# CIC register map
Vendor: Texas Instruments
Peripheral module from a debugger description file (folder 66AK2G0x_66AK2G1x).
Registers are 32-bit, read-write, reset 0x0 unless marked. A register's access mark holds for its fields unless they carry their own. Offsets are as the file gives them; lines under a group give offsets from that group; [hi:lo] are bit positions; {n}, {i} and the like mark numbered series; 'fields as' and 'values as' point back to an identical list; <NAME> marks a mode.

## CIC
0x00 CIC_REVISION_REG ro reset 0x4E82A900
  [31:0] REV — TI internal data. Identifies revision of peripheral.
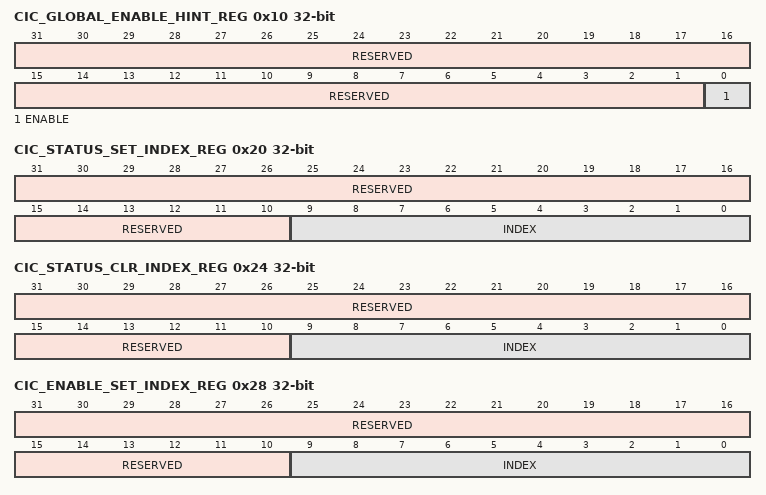
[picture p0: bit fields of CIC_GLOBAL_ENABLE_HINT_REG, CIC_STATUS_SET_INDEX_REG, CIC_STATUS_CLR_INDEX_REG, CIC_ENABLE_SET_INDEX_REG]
0x10 CIC_GLOBAL_ENABLE_HINT_REG access per field
  [31:1] RESERVED ro — Reads return 0 and writes have no effect.
  [0] ENABLE rw — This field enables or disables all the host interrupts at once. Reads return the current global enable value. When written:
0x20 CIC_STATUS_SET_INDEX_REG access per field
  [31:10] RESERVED ro — Reads return 0 and writes have no effect.
  [9:0] INDEX rw — This field allows setting the status of an interrupt. Reads return 0. Writes set the status of the interrupt given in the index value.
0x24 CIC_STATUS_CLR_INDEX_REG access per field
  [31:10] RESERVED ro — Reads return 0 and writes have no effect.
  [9:0] INDEX rw — This field allows clearing the status of an interrupt. Reads return 0. Writes clear the status of the interrupt given in the index value.
0x28 CIC_ENABLE_SET_INDEX_REG access per field
  [31:10] RESERVED ro — Reads return 0 and writes have no effect.
  [9:0] INDEX rw — This field allows enabling an interrupt. Reads return 0. Writes set the enable of the interrupt given in the index value.
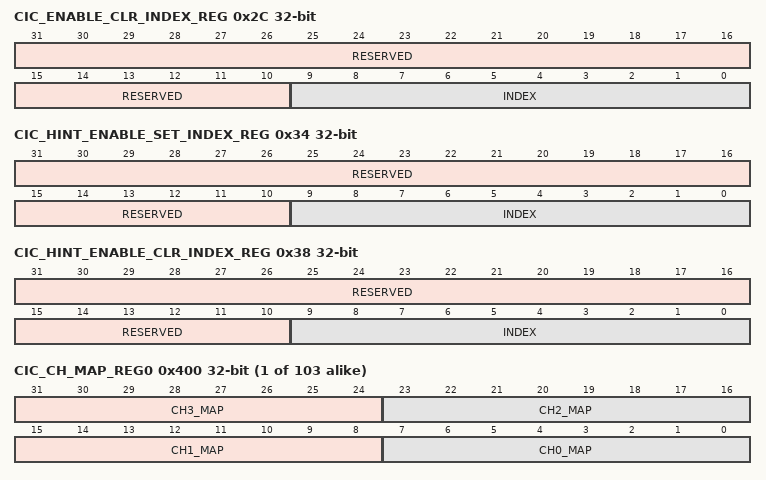
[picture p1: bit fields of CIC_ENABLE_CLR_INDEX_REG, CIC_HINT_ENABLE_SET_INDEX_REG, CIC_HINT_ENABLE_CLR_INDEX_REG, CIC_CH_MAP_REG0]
0x2C CIC_ENABLE_CLR_INDEX_REG access per field
  [31:10] RESERVED ro — Reads return 0 and writes have no effect.
  [9:0] INDEX rw — This field allows disabling an interrupt. Reads return 0. Writes clear the enable of the interrupt given in the index value.
0x34 CIC_HINT_ENABLE_SET_INDEX_REG access per field
  [31:10] RESERVED ro — Reads return 0 and writes have no effect.
  [9:0] INDEX rw — This field allows enabling a host interrupt output. Reads return 0. Writes set the enable of the host interrupt given in the index value.
0x38 CIC_HINT_ENABLE_CLR_INDEX_REG access per field
  [31:10] RESERVED ro — Reads return 0 and writes have no effect.
  [9:0] INDEX rw — This field allows disabling a host interrupt output. Reads return 0. Writes clear the enable of the host interrupt given in the index value.
{0x200+4i} CIC_RAW_STATUS_REG{i} (i=0..11)
  [31:0] RAW_STATUS — System interrupt raw status and setting. Reads return the raw status. When written (per bit position):
{0x280+4i} CIC_ENA_STATUS_REG{i} (i=0..11)
  [31:0] ENABLED_STATUS — System interrupt enabled status and clearing. Reads return the enabled status (before enabling with the System Interrupt Enable Set Registers). When written (per bit position):
{0x300+4i} CIC_ENABLE_REG{i} (i=0..11)
  [31:0] ENABLE — System interrupt enables.Read returns the enable value: When written (per bit position):
{0x380+4i} CIC_ENABLE_CLR_REG{i} (i=0..11)
  [31:0] ENABLE — System interrupt disables.Read returns the enable value: When written (per bit position):
{0x400+4i} CIC_CH_MAP_REG{i} (i=0..102)
  [31:24] CH3_MAP — Set the channel for the system interrupt N + 3
  [23:16] CH2_MAP — Set the channel for the system interrupt N + 2
  [15:8] CH1_MAP — Set the channel for the system interrupt N + 1
  [7:0] CH0_MAP — Set the channel for the system interrupt N
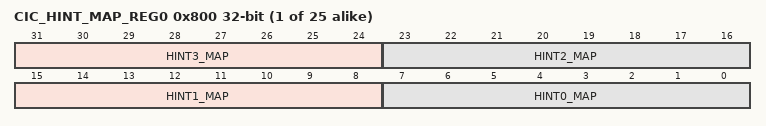
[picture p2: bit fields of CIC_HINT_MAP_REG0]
{0x800+4i} CIC_HINT_MAP_REG{i} ro (i=0..24)
  [31:24] HINT3_MAP — Set the host interrupt for channel N + 3
  [23:16] HINT2_MAP — Set the host interrupt for channel N + 2
  [15:8] HINT1_MAP — Set the host interrupt for channel N + 1
  [7:0] HINT0_MAP — Set the host interrupt for channel N
{0x1500+4i} CIC_ENABLE_HINT_REG{i} (i=0..2)
  [31:0] ENABLES — This field enables the host interrupts. When written (per bit position):
